VERSION ""

NS_ :

BS_:

BU_: Vector__XXX

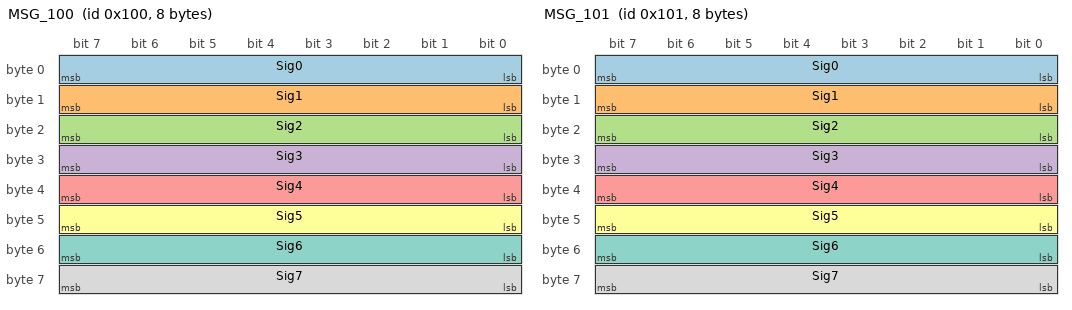
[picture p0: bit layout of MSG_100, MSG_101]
BO_ 256 MSG_100: 8 Vector__XXX
 SG_ Sig0 : 0|8@1+ (0.5,0) [0|127] "u0" Vector__XXX
 SG_ Sig1 : 8|8@1+ (0.5,1) [0|127] "u1" Vector__XXX
 SG_ Sig2 : 16|8@1+ (0.5,2) [0|127] "u2" Vector__XXX
 SG_ Sig3 : 24|8@1+ (0.5,3) [0|127] "u3" Vector__XXX
 SG_ Sig4 : 32|8@1+ (0.5,4) [0|127] "u4" Vector__XXX
 SG_ Sig5 : 40|8@1+ (0.5,5) [0|127] "u5" Vector__XXX
 SG_ Sig6 : 48|8@1+ (0.5,6) [0|127] "u6" Vector__XXX
 SG_ Sig7 : 56|8@1+ (0.5,7) [0|127] "u7" Vector__XXX

BO_ 257 MSG_101: 8 Vector__XXX
 SG_ Sig0 : 0|8@1+ (0.5,0) [0|127] "u0" Vector__XXX
 SG_ Sig1 : 8|8@1+ (0.5,1) [0|127] "u1" Vector__XXX
 SG_ Sig2 : 16|8@1+ (0.5,2) [0|127] "u2" Vector__XXX
 SG_ Sig3 : 24|8@1+ (0.5,3) [0|127] "u3" Vector__XXX
 SG_ Sig4 : 32|8@1+ (0.5,4) [0|127] "u4" Vector__XXX
 SG_ Sig5 : 40|8@1+ (0.5,5) [0|127] "u5" Vector__XXX
 SG_ Sig6 : 48|8@1+ (0.5,6) [0|127] "u6" Vector__XXX
 SG_ Sig7 : 56|8@1+ (0.5,7) [0|127] "u7" Vector__XXX

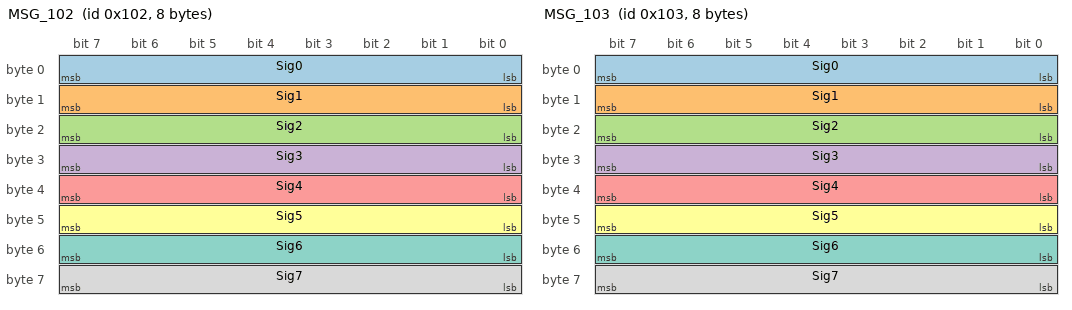
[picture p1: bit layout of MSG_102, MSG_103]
BO_ 258 MSG_102: 8 Vector__XXX
 SG_ Sig0 : 0|8@1+ (0.5,0) [0|127] "u0" Vector__XXX
 SG_ Sig1 : 8|8@1+ (0.5,1) [0|127] "u1" Vector__XXX
 SG_ Sig2 : 16|8@1+ (0.5,2) [0|127] "u2" Vector__XXX
 SG_ Sig3 : 24|8@1+ (0.5,3) [0|127] "u3" Vector__XXX
 SG_ Sig4 : 32|8@1+ (0.5,4) [0|127] "u4" Vector__XXX
 SG_ Sig5 : 40|8@1+ (0.5,5) [0|127] "u5" Vector__XXX
 SG_ Sig6 : 48|8@1+ (0.5,6) [0|127] "u6" Vector__XXX
 SG_ Sig7 : 56|8@1+ (0.5,7) [0|127] "u7" Vector__XXX

BO_ 259 MSG_103: 8 Vector__XXX
 SG_ Sig0 : 0|8@1+ (0.5,0) [0|127] "u0" Vector__XXX
 SG_ Sig1 : 8|8@1+ (0.5,1) [0|127] "u1" Vector__XXX
 SG_ Sig2 : 16|8@1+ (0.5,2) [0|127] "u2" Vector__XXX
 SG_ Sig3 : 24|8@1+ (0.5,3) [0|127] "u3" Vector__XXX
 SG_ Sig4 : 32|8@1+ (0.5,4) [0|127] "u4" Vector__XXX
 SG_ Sig5 : 40|8@1+ (0.5,5) [0|127] "u5" Vector__XXX
 SG_ Sig6 : 48|8@1+ (0.5,6) [0|127] "u6" Vector__XXX
 SG_ Sig7 : 56|8@1+ (0.5,7) [0|127] "u7" Vector__XXX

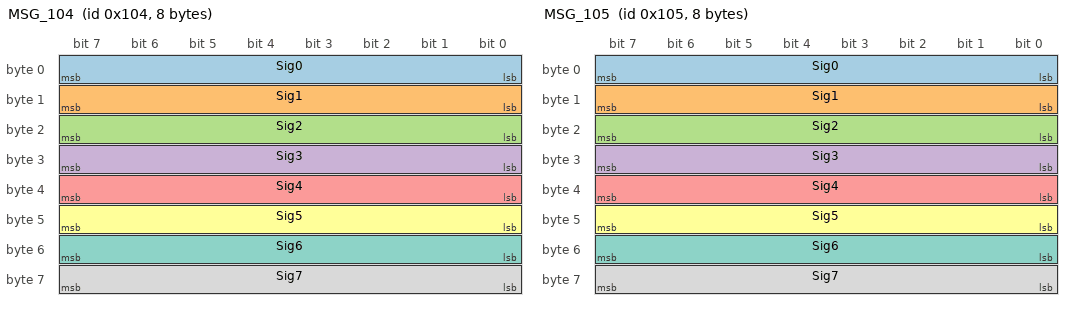
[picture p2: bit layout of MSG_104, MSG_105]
BO_ 260 MSG_104: 8 Vector__XXX
 SG_ Sig0 : 0|8@1+ (0.5,0) [0|127] "u0" Vector__XXX
 SG_ Sig1 : 8|8@1+ (0.5,1) [0|127] "u1" Vector__XXX
 SG_ Sig2 : 16|8@1+ (0.5,2) [0|127] "u2" Vector__XXX
 SG_ Sig3 : 24|8@1+ (0.5,3) [0|127] "u3" Vector__XXX
 SG_ Sig4 : 32|8@1+ (0.5,4) [0|127] "u4" Vector__XXX
 SG_ Sig5 : 40|8@1+ (0.5,5) [0|127] "u5" Vector__XXX
 SG_ Sig6 : 48|8@1+ (0.5,6) [0|127] "u6" Vector__XXX
 SG_ Sig7 : 56|8@1+ (0.5,7) [0|127] "u7" Vector__XXX

BO_ 261 MSG_105: 8 Vector__XXX
 SG_ Sig0 : 0|8@1+ (0.5,0) [0|127] "u0" Vector__XXX
 SG_ Sig1 : 8|8@1+ (0.5,1) [0|127] "u1" Vector__XXX
 SG_ Sig2 : 16|8@1+ (0.5,2) [0|127] "u2" Vector__XXX
 SG_ Sig3 : 24|8@1+ (0.5,3) [0|127] "u3" Vector__XXX
 SG_ Sig4 : 32|8@1+ (0.5,4) [0|127] "u4" Vector__XXX
 SG_ Sig5 : 40|8@1+ (0.5,5) [0|127] "u5" Vector__XXX
 SG_ Sig6 : 48|8@1+ (0.5,6) [0|127] "u6" Vector__XXX
 SG_ Sig7 : 56|8@1+ (0.5,7) [0|127] "u7" Vector__XXX

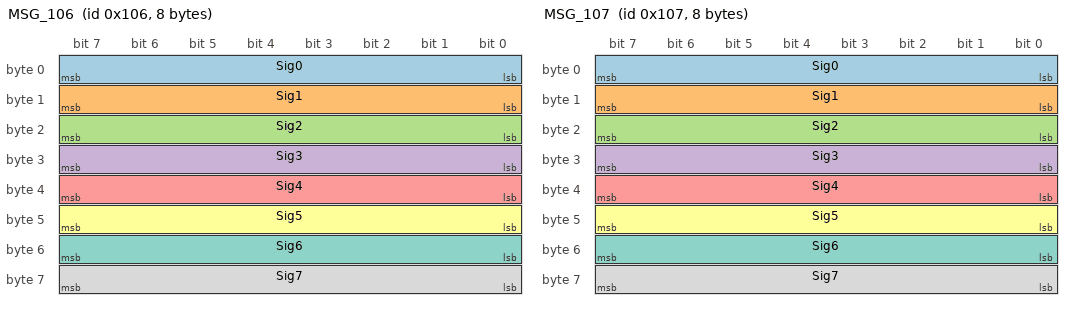
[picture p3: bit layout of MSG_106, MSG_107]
BO_ 262 MSG_106: 8 Vector__XXX
 SG_ Sig0 : 0|8@1+ (0.5,0) [0|127] "u0" Vector__XXX
 SG_ Sig1 : 8|8@1+ (0.5,1) [0|127] "u1" Vector__XXX
 SG_ Sig2 : 16|8@1+ (0.5,2) [0|127] "u2" Vector__XXX
 SG_ Sig3 : 24|8@1+ (0.5,3) [0|127] "u3" Vector__XXX
 SG_ Sig4 : 32|8@1+ (0.5,4) [0|127] "u4" Vector__XXX
 SG_ Sig5 : 40|8@1+ (0.5,5) [0|127] "u5" Vector__XXX
 SG_ Sig6 : 48|8@1+ (0.5,6) [0|127] "u6" Vector__XXX
 SG_ Sig7 : 56|8@1+ (0.5,7) [0|127] "u7" Vector__XXX

BO_ 263 MSG_107: 8 Vector__XXX
 SG_ Sig0 : 0|8@1+ (0.5,0) [0|127] "u0" Vector__XXX
 SG_ Sig1 : 8|8@1+ (0.5,1) [0|127] "u1" Vector__XXX
 SG_ Sig2 : 16|8@1+ (0.5,2) [0|127] "u2" Vector__XXX
 SG_ Sig3 : 24|8@1+ (0.5,3) [0|127] "u3" Vector__XXX
 SG_ Sig4 : 32|8@1+ (0.5,4) [0|127] "u4" Vector__XXX
 SG_ Sig5 : 40|8@1+ (0.5,5) [0|127] "u5" Vector__XXX
 SG_ Sig6 : 48|8@1+ (0.5,6) [0|127] "u6" Vector__XXX
 SG_ Sig7 : 56|8@1+ (0.5,7) [0|127] "u7" Vector__XXX

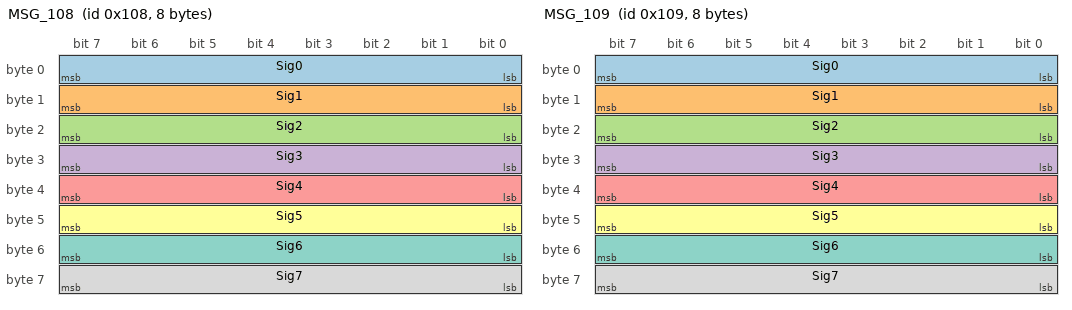
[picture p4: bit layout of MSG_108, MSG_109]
BO_ 264 MSG_108: 8 Vector__XXX
 SG_ Sig0 : 0|8@1+ (0.5,0) [0|127] "u0" Vector__XXX
 SG_ Sig1 : 8|8@1+ (0.5,1) [0|127] "u1" Vector__XXX
 SG_ Sig2 : 16|8@1+ (0.5,2) [0|127] "u2" Vector__XXX
 SG_ Sig3 : 24|8@1+ (0.5,3) [0|127] "u3" Vector__XXX
 SG_ Sig4 : 32|8@1+ (0.5,4) [0|127] "u4" Vector__XXX
 SG_ Sig5 : 40|8@1+ (0.5,5) [0|127] "u5" Vector__XXX
 SG_ Sig6 : 48|8@1+ (0.5,6) [0|127] "u6" Vector__XXX
 SG_ Sig7 : 56|8@1+ (0.5,7) [0|127] "u7" Vector__XXX

BO_ 265 MSG_109: 8 Vector__XXX
 SG_ Sig0 : 0|8@1+ (0.5,0) [0|127] "u0" Vector__XXX
 SG_ Sig1 : 8|8@1+ (0.5,1) [0|127] "u1" Vector__XXX
 SG_ Sig2 : 16|8@1+ (0.5,2) [0|127] "u2" Vector__XXX
 SG_ Sig3 : 24|8@1+ (0.5,3) [0|127] "u3" Vector__XXX
 SG_ Sig4 : 32|8@1+ (0.5,4) [0|127] "u4" Vector__XXX
 SG_ Sig5 : 40|8@1+ (0.5,5) [0|127] "u5" Vector__XXX
 SG_ Sig6 : 48|8@1+ (0.5,6) [0|127] "u6" Vector__XXX
 SG_ Sig7 : 56|8@1+ (0.5,7) [0|127] "u7" Vector__XXX

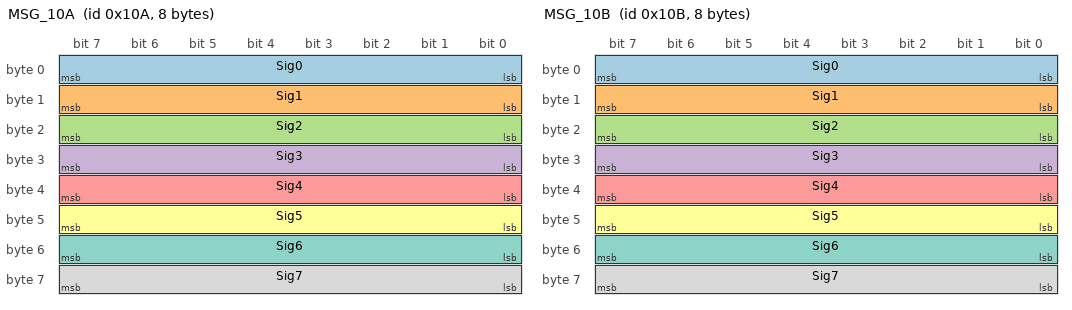
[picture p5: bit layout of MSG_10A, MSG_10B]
BO_ 266 MSG_10A: 8 Vector__XXX
 SG_ Sig0 : 0|8@1+ (0.5,0) [0|127] "u0" Vector__XXX
 SG_ Sig1 : 8|8@1+ (0.5,1) [0|127] "u1" Vector__XXX
 SG_ Sig2 : 16|8@1+ (0.5,2) [0|127] "u2" Vector__XXX
 SG_ Sig3 : 24|8@1+ (0.5,3) [0|127] "u3" Vector__XXX
 SG_ Sig4 : 32|8@1+ (0.5,4) [0|127] "u4" Vector__XXX
 SG_ Sig5 : 40|8@1+ (0.5,5) [0|127] "u5" Vector__XXX
 SG_ Sig6 : 48|8@1+ (0.5,6) [0|127] "u6" Vector__XXX
 SG_ Sig7 : 56|8@1+ (0.5,7) [0|127] "u7" Vector__XXX

BO_ 267 MSG_10B: 8 Vector__XXX
 SG_ Sig0 : 0|8@1+ (0.5,0) [0|127] "u0" Vector__XXX
 SG_ Sig1 : 8|8@1+ (0.5,1) [0|127] "u1" Vector__XXX
 SG_ Sig2 : 16|8@1+ (0.5,2) [0|127] "u2" Vector__XXX
 SG_ Sig3 : 24|8@1+ (0.5,3) [0|127] "u3" Vector__XXX
 SG_ Sig4 : 32|8@1+ (0.5,4) [0|127] "u4" Vector__XXX
 SG_ Sig5 : 40|8@1+ (0.5,5) [0|127] "u5" Vector__XXX
 SG_ Sig6 : 48|8@1+ (0.5,6) [0|127] "u6" Vector__XXX
 SG_ Sig7 : 56|8@1+ (0.5,7) [0|127] "u7" Vector__XXX

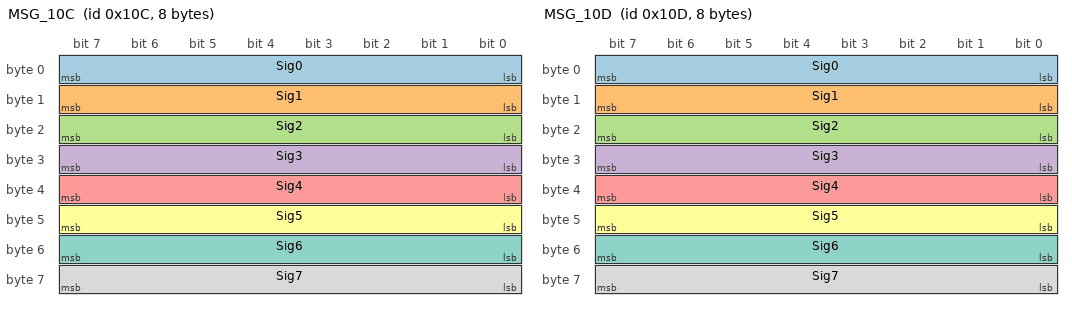
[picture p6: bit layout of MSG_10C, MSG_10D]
BO_ 268 MSG_10C: 8 Vector__XXX
 SG_ Sig0 : 0|8@1+ (0.5,0) [0|127] "u0" Vector__XXX
 SG_ Sig1 : 8|8@1+ (0.5,1) [0|127] "u1" Vector__XXX
 SG_ Sig2 : 16|8@1+ (0.5,2) [0|127] "u2" Vector__XXX
 SG_ Sig3 : 24|8@1+ (0.5,3) [0|127] "u3" Vector__XXX
 SG_ Sig4 : 32|8@1+ (0.5,4) [0|127] "u4" Vector__XXX
 SG_ Sig5 : 40|8@1+ (0.5,5) [0|127] "u5" Vector__XXX
 SG_ Sig6 : 48|8@1+ (0.5,6) [0|127] "u6" Vector__XXX
 SG_ Sig7 : 56|8@1+ (0.5,7) [0|127] "u7" Vector__XXX

BO_ 269 MSG_10D: 8 Vector__XXX
 SG_ Sig0 : 0|8@1+ (0.5,0) [0|127] "u0" Vector__XXX
 SG_ Sig1 : 8|8@1+ (0.5,1) [0|127] "u1" Vector__XXX
 SG_ Sig2 : 16|8@1+ (0.5,2) [0|127] "u2" Vector__XXX
 SG_ Sig3 : 24|8@1+ (0.5,3) [0|127] "u3" Vector__XXX
 SG_ Sig4 : 32|8@1+ (0.5,4) [0|127] "u4" Vector__XXX
 SG_ Sig5 : 40|8@1+ (0.5,5) [0|127] "u5" Vector__XXX
 SG_ Sig6 : 48|8@1+ (0.5,6) [0|127] "u6" Vector__XXX
 SG_ Sig7 : 56|8@1+ (0.5,7) [0|127] "u7" Vector__XXX

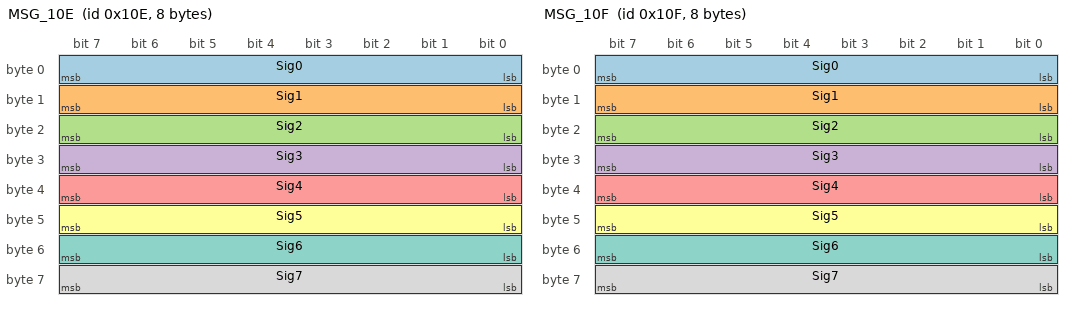
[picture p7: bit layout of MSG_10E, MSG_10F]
BO_ 270 MSG_10E: 8 Vector__XXX
 SG_ Sig0 : 0|8@1+ (0.5,0) [0|127] "u0" Vector__XXX
 SG_ Sig1 : 8|8@1+ (0.5,1) [0|127] "u1" Vector__XXX
 SG_ Sig2 : 16|8@1+ (0.5,2) [0|127] "u2" Vector__XXX
 SG_ Sig3 : 24|8@1+ (0.5,3) [0|127] "u3" Vector__XXX
 SG_ Sig4 : 32|8@1+ (0.5,4) [0|127] "u4" Vector__XXX
 SG_ Sig5 : 40|8@1+ (0.5,5) [0|127] "u5" Vector__XXX
 SG_ Sig6 : 48|8@1+ (0.5,6) [0|127] "u6" Vector__XXX
 SG_ Sig7 : 56|8@1+ (0.5,7) [0|127] "u7" Vector__XXX

BO_ 271 MSG_10F: 8 Vector__XXX
 SG_ Sig0 : 0|8@1+ (0.5,0) [0|127] "u0" Vector__XXX
 SG_ Sig1 : 8|8@1+ (0.5,1) [0|127] "u1" Vector__XXX
 SG_ Sig2 : 16|8@1+ (0.5,2) [0|127] "u2" Vector__XXX
 SG_ Sig3 : 24|8@1+ (0.5,3) [0|127] "u3" Vector__XXX
 SG_ Sig4 : 32|8@1+ (0.5,4) [0|127] "u4" Vector__XXX
 SG_ Sig5 : 40|8@1+ (0.5,5) [0|127] "u5" Vector__XXX
 SG_ Sig6 : 48|8@1+ (0.5,6) [0|127] "u6" Vector__XXX
 SG_ Sig7 : 56|8@1+ (0.5,7) [0|127] "u7" Vector__XXX

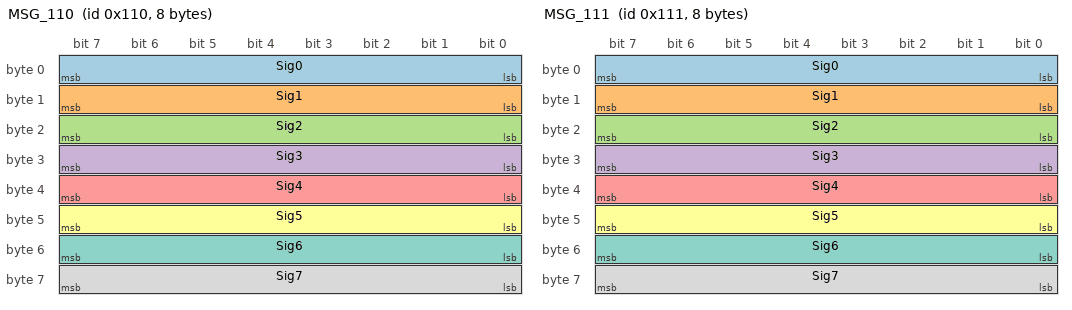
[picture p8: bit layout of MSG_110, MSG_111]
BO_ 272 MSG_110: 8 Vector__XXX
 SG_ Sig0 : 0|8@1+ (0.5,0) [0|127] "u0" Vector__XXX
 SG_ Sig1 : 8|8@1+ (0.5,1) [0|127] "u1" Vector__XXX
 SG_ Sig2 : 16|8@1+ (0.5,2) [0|127] "u2" Vector__XXX
 SG_ Sig3 : 24|8@1+ (0.5,3) [0|127] "u3" Vector__XXX
 SG_ Sig4 : 32|8@1+ (0.5,4) [0|127] "u4" Vector__XXX
 SG_ Sig5 : 40|8@1+ (0.5,5) [0|127] "u5" Vector__XXX
 SG_ Sig6 : 48|8@1+ (0.5,6) [0|127] "u6" Vector__XXX
 SG_ Sig7 : 56|8@1+ (0.5,7) [0|127] "u7" Vector__XXX

BO_ 273 MSG_111: 8 Vector__XXX
 SG_ Sig0 : 0|8@1+ (0.5,0) [0|127] "u0" Vector__XXX
 SG_ Sig1 : 8|8@1+ (0.5,1) [0|127] "u1" Vector__XXX
 SG_ Sig2 : 16|8@1+ (0.5,2) [0|127] "u2" Vector__XXX
 SG_ Sig3 : 24|8@1+ (0.5,3) [0|127] "u3" Vector__XXX
 SG_ Sig4 : 32|8@1+ (0.5,4) [0|127] "u4" Vector__XXX
 SG_ Sig5 : 40|8@1+ (0.5,5) [0|127] "u5" Vector__XXX
 SG_ Sig6 : 48|8@1+ (0.5,6) [0|127] "u6" Vector__XXX
 SG_ Sig7 : 56|8@1+ (0.5,7) [0|127] "u7" Vector__XXX

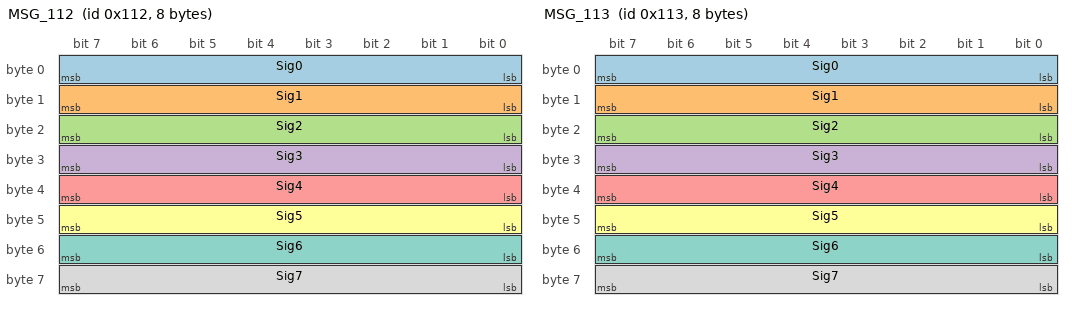
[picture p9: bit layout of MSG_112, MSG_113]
BO_ 274 MSG_112: 8 Vector__XXX
 SG_ Sig0 : 0|8@1+ (0.5,0) [0|127] "u0" Vector__XXX
 SG_ Sig1 : 8|8@1+ (0.5,1) [0|127] "u1" Vector__XXX
 SG_ Sig2 : 16|8@1+ (0.5,2) [0|127] "u2" Vector__XXX
 SG_ Sig3 : 24|8@1+ (0.5,3) [0|127] "u3" Vector__XXX
 SG_ Sig4 : 32|8@1+ (0.5,4) [0|127] "u4" Vector__XXX
 SG_ Sig5 : 40|8@1+ (0.5,5) [0|127] "u5" Vector__XXX
 SG_ Sig6 : 48|8@1+ (0.5,6) [0|127] "u6" Vector__XXX
 SG_ Sig7 : 56|8@1+ (0.5,7) [0|127] "u7" Vector__XXX

BO_ 275 MSG_113: 8 Vector__XXX
 SG_ Sig0 : 0|8@1+ (0.5,0) [0|127] "u0" Vector__XXX
 SG_ Sig1 : 8|8@1+ (0.5,1) [0|127] "u1" Vector__XXX
 SG_ Sig2 : 16|8@1+ (0.5,2) [0|127] "u2" Vector__XXX
 SG_ Sig3 : 24|8@1+ (0.5,3) [0|127] "u3" Vector__XXX
 SG_ Sig4 : 32|8@1+ (0.5,4) [0|127] "u4" Vector__XXX
 SG_ Sig5 : 40|8@1+ (0.5,5) [0|127] "u5" Vector__XXX
 SG_ Sig6 : 48|8@1+ (0.5,6) [0|127] "u6" Vector__XXX
 SG_ Sig7 : 56|8@1+ (0.5,7) [0|127] "u7" Vector__XXX

BO_ 512 MSG_200: 8 Vector__XXX
 SG_ Sig0 : 0|8@1+ (1,0) [0|255] "" Vector__XXX

BO_ 28036591 MSG_1ABCDEF: 8 Vector__XXX
 SG_ Sig0 : 0|8@1+ (1,0) [0|255] "" Vector__XXX

BO_ 768 MSG_300: 8 Vector__XXX
 SG_ Sig0 : 0|8@1+ (1,0) [0|255] "" Vector__XXX

BO_ 1024 MSG_400: 8 Vector__XXX
 SG_ Sig0 : 0|8@1+ (1,0) [0|255] "" Vector__XXX

BO_ 1520 FD_MSG: 64 Vector__XXX
 SG_ Pay : 0|8@1+ (1,0) [0|255] "V" Vector__XXX
